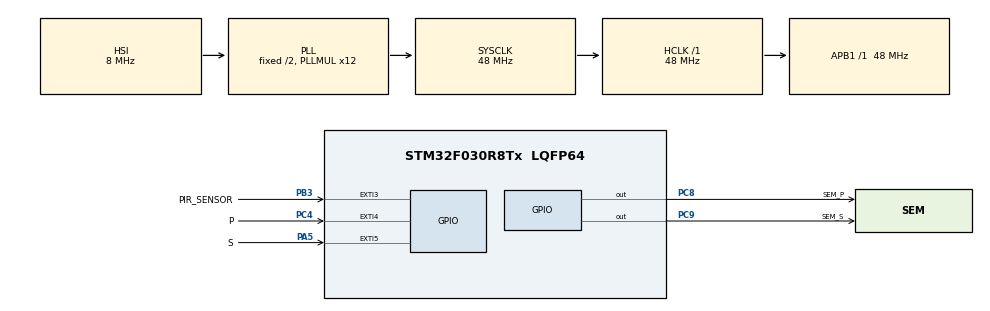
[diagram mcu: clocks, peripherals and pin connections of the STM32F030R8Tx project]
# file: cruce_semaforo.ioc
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Mcu.Family=STM32F0
Mcu.Name=STM32F030R8Tx
Mcu.Package=LQFP64
NVIC.EXTI2_3_IRQn=true\:0\:0\:false\:false\:true\:true
NVIC.EXTI4_15_IRQn=true\:0\:0\:false\:false\:true\:true
NVIC.TIM6_IRQn=true\:0\:0\:false\:false\:true\:true
PA13.GPIO_Label=SWDIO
PA13.Signal=SYS_SWDIO
PA14.GPIO_Label=SWCLK
PA14.Signal=SYS_SWCLK
PA5.GPIO_Label=S
PA5.GPIO_ModeDefaultEXTI=GPIO_MODE_IT_FALLING
PA5.GPIO_PuPd=GPIO_PULLUP
PA5.Signal=GPXTI5
PB3.GPIO_Label=PIR_SENSOR
PB3.GPIO_ModeDefaultEXTI=GPIO_MODE_IT_RISING
PB3.GPIO_PuPd=GPIO_PULLDOWN
PB3.Signal=GPXTI3
PC4.GPIO_Label=P
PC4.GPIO_PuPd=GPIO_PULLUP
PC4.Signal=GPXTI4
PC8.GPIO_Label=SEM_P
PC8.Signal=GPIO_Output
PC9.GPIO_Label=SEM_S
PC9.Signal=GPIO_Output
ProjectManager.HeapSize=0x200
ProjectManager.StackSize=0x400
ProjectManager.TargetToolchain=SW4STM32
RCC.AHBFreq_Value=48000000
RCC.APB1Freq_Value=48000000
RCC.APB1TimFreq_Value=48000000
RCC.HCLKFreq_Value=48000000
RCC.PLLMUL=RCC_PLL_MUL12
RCC.SYSCLKFreq_VALUE=48000000
RCC.SYSCLKSource=RCC_SYSCLKSOURCE_PLLCLK
TIM14.Period=29
TIM14.Prescaler=47999
TIM16.AutoReloadPreload=TIM_AUTORELOAD_PRELOAD_ENABLE
TIM16.Period=200
TIM16.Prescaler=47999
TIM17.AutoReloadPreload=TIM_AUTORELOAD_PRELOAD_ENABLE
TIM17.Period=200
TIM17.Prescaler=47999
TIM6.AutoReloadPreload=TIM_AUTORELOAD_PRELOAD_DISABLE
TIM6.Period=29
TIM6.Prescaler=47999
VP_TIM14_VS_ClockSourceINT.Mode=Enable_Timer
VP_TIM16_VS_ClockSourceINT.Mode=Enable_Timer
VP_TIM17_VS_ClockSourceINT.Mode=Enable_Timer
VP_TIM6_VS_ClockSourceINT.Mode=Enable_Timer
board=STM32F0308-DISCO

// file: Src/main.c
/**
  ******************************************************************************
  * @file           : main.c
  * @brief          : Main program body
  ******************************************************************************
  ** This notice applies to any and all portions of this file
  * that are not between comment pairs USER CODE BEGIN and
  * USER CODE END. Other portions of this file, whether
  * inserted by the user or by software development tools
  * are owned by their respective copyright owners.
  *
  * COPYRIGHT(c) 2018 STMicroelectronics
  *
  * Redistribution and use in source and binary forms, with or without modification,
  * are permitted provided that the following conditions are met:
  *   1. Redistributions of source code must retain the above copyright notice,
  *      this list of conditions and the following disclaimer.
  *   2. Redistributions in binary form must reproduce the above copyright notice,
  *      this list of conditions and the following disclaimer in the documentation
  *      and/or other materials provided with the distribution.
  *   3. Neither the name of STMicroelectronics nor the names of its contributors
  *      may be used to endorse or promote products derived from this software
  *      without specific prior written permission.
  *
  * THIS SOFTWARE IS PROVIDED BY THE COPYRIGHT HOLDERS AND CONTRIBUTORS "AS IS"
  * AND ANY EXPRESS OR IMPLIED WARRANTIES, INCLUDING, BUT NOT LIMITED TO, THE
  * IMPLIED WARRANTIES OF MERCHANTABILITY AND FITNESS FOR A PARTICULAR PURPOSE ARE
  * DISCLAIMED. IN NO EVENT SHALL THE COPYRIGHT HOLDER OR CONTRIBUTORS BE LIABLE
  * FOR ANY DIRECT, INDIRECT, INCIDENTAL, SPECIAL, EXEMPLARY, OR CONSEQUENTIAL
  * DAMAGES (INCLUDING, BUT NOT LIMITED TO, PROCUREMENT OF SUBSTITUTE GOODS OR
  * SERVICES; LOSS OF USE, DATA, OR PROFITS; OR BUSINESS INTERRUPTION) HOWEVER
  * CAUSED AND ON ANY THEORY OF LIABILITY, WHETHER IN CONTRACT, STRICT LIABILITY,
  * OR TORT (INCLUDING NEGLIGENCE OR OTHERWISE) ARISING IN ANY WAY OUT OF THE USE
  * OF THIS SOFTWARE, EVEN IF ADVISED OF THE POSSIBILITY OF SUCH DAMAGE.
  *
  ******************************************************************************
  */
#include "main.h"
#include "stm32f0xx_hal.h"

/* USER CODE BEGIN Includes */
#include "sem_fsm.h"
#include "fsm.h"
/* USER CODE END Includes */

TIM_HandleTypeDef htim6;
TIM_HandleTypeDef htim14;
TIM_HandleTypeDef htim16;
TIM_HandleTypeDef htim17;

/* USER CODE BEGIN PV */
/* Private variables ---------------------------------------------------------*/
uint32_t now,last,period;
/* USER CODE END PV */

void SystemClock_Config(void);
static void MX_GPIO_Init(void);
static void MX_TIM6_Init(void);
static void MX_TIM14_Init(void);
static void MX_TIM16_Init(void);
static void MX_TIM17_Init(void);

/* USER CODE BEGIN PFP */
/* Private function prototypes -----------------------------------------------*/

/* USER CODE END PFP */

int main(void)
{

  /* MCU Configuration----------------------------------------------------------*/

  /* Reset of all peripherals, Initializes the Flash interface and the Systick. */
  HAL_Init();

  /* Configure the system clock */
  SystemClock_Config();

  /* Initialize all configured peripherals */
  MX_GPIO_Init();
  MX_TIM6_Init();
  MX_TIM14_Init();
  MX_TIM16_Init();
  MX_TIM17_Init();
  /* USER CODE BEGIN 2 */
  systick_preescaler = 0;
  fsm_t * sem_p_fsm = new_sem_p_fsm();
  fsm_t * sem_s_fsm = new_sem_s_fsm();
  /* USER CODE END 2 */

  /* Infinite loop */
  /* USER CODE BEGIN WHILE */
  last = HAL_GetTick();
  period = 100;
  while (1)
  {
	 fsm_fire(sem_p_fsm);
	 fsm_fire(sem_s_fsm);
	 now = HAL_GetTick();
	 HAL_Delay( period - (now - last));
	 last = HAL_GetTick();

  /* USER CODE END WHILE */

  }

}

void SystemClock_Config(void)
{

  RCC_OscInitTypeDef RCC_OscInitStruct;
  RCC_ClkInitTypeDef RCC_ClkInitStruct;

    /**Initializes the CPU, AHB and APB busses clocks
    */
  RCC_OscInitStruct.OscillatorType = RCC_OSCILLATORTYPE_HSI;
  RCC_OscInitStruct.HSIState = RCC_HSI_ON;
  RCC_OscInitStruct.HSICalibrationValue = 16;
  RCC_OscInitStruct.PLL.PLLState = RCC_PLL_ON;
  RCC_OscInitStruct.PLL.PLLSource = RCC_PLLSOURCE_HSI;
  RCC_OscInitStruct.PLL.PLLMUL = RCC_PLL_MUL12;
  RCC_OscInitStruct.PLL.PREDIV = RCC_PREDIV_DIV1;
  if (HAL_RCC_OscConfig(&RCC_OscInitStruct) != HAL_OK)
  {
    _Error_Handler(__FILE__, __LINE__);
  }

    /**Initializes the CPU, AHB and APB busses clocks
    */
  RCC_ClkInitStruct.ClockType = RCC_CLOCKTYPE_HCLK|RCC_CLOCKTYPE_SYSCLK
                              |RCC_CLOCKTYPE_PCLK1;
  RCC_ClkInitStruct.SYSCLKSource = RCC_SYSCLKSOURCE_PLLCLK;
  RCC_ClkInitStruct.AHBCLKDivider = RCC_SYSCLK_DIV1;
  RCC_ClkInitStruct.APB1CLKDivider = RCC_HCLK_DIV1;

  if (HAL_RCC_ClockConfig(&RCC_ClkInitStruct, FLASH_LATENCY_1) != HAL_OK)
  {
    _Error_Handler(__FILE__, __LINE__);
  }

    /**Configure the Systick interrupt time
    */
  HAL_SYSTICK_Config(HAL_RCC_GetHCLKFreq()/1000);

    /**Configure the Systick
    */
  HAL_SYSTICK_CLKSourceConfig(SYSTICK_CLKSOURCE_HCLK);

  /* SysTick_IRQn interrupt configuration */
  HAL_NVIC_SetPriority(SysTick_IRQn, 0, 0);
}

/* TIM6 init function */
static void MX_TIM6_Init(void)
{

  htim6.Instance = TIM6;
  htim6.Init.Prescaler = 47999;
  htim6.Init.CounterMode = TIM_COUNTERMODE_UP;
  htim6.Init.Period = 29;
  htim6.Init.AutoReloadPreload = TIM_AUTORELOAD_PRELOAD_DISABLE;
  if (HAL_TIM_Base_Init(&htim6) != HAL_OK)
  {
    _Error_Handler(__FILE__, __LINE__);
  }

}

/* TIM14 init function */
static void MX_TIM14_Init(void)
{

  htim14.Instance = TIM14;
  htim14.Init.Prescaler = 47999;
  htim14.Init.CounterMode = TIM_COUNTERMODE_UP;
  htim14.Init.Period = 29;
  htim14.Init.ClockDivision = TIM_CLOCKDIVISION_DIV1;
  htim14.Init.AutoReloadPreload = TIM_AUTORELOAD_PRELOAD_DISABLE;
  if (HAL_TIM_Base_Init(&htim14) != HAL_OK)
  {
    _Error_Handler(__FILE__, __LINE__);
  }

}

/* TIM16 init function */
static void MX_TIM16_Init(void)
{

  htim16.Instance = TIM16;
  htim16.Init.Prescaler = 47999;
  htim16.Init.CounterMode = TIM_COUNTERMODE_UP;
  htim16.Init.Period = 200;
  htim16.Init.ClockDivision = TIM_CLOCKDIVISION_DIV1;
  htim16.Init.RepetitionCounter = 0;
  htim16.Init.AutoReloadPreload = TIM_AUTORELOAD_PRELOAD_ENABLE;
  if (HAL_TIM_Base_Init(&htim16) != HAL_OK)
  {
    _Error_Handler(__FILE__, __LINE__);
  }

}

/* TIM17 init function */
static void MX_TIM17_Init(void)
{

  htim17.Instance = TIM17;
  htim17.Init.Prescaler = 47999;
  htim17.Init.CounterMode = TIM_COUNTERMODE_UP;
  htim17.Init.Period = 200;
  htim17.Init.ClockDivision = TIM_CLOCKDIVISION_DIV1;
  htim17.Init.RepetitionCounter = 0;
  htim17.Init.AutoReloadPreload = TIM_AUTORELOAD_PRELOAD_ENABLE;
  if (HAL_TIM_Base_Init(&htim17) != HAL_OK)
  {
    _Error_Handler(__FILE__, __LINE__);
  }

}

/** Configure pins as
        * Analog
        * Input
        * Output
        * EVENT_OUT
        * EXTI
*/
static void MX_GPIO_Init(void)
{

  GPIO_InitTypeDef GPIO_InitStruct;

  /* GPIO Ports Clock Enable */
  __HAL_RCC_GPIOA_CLK_ENABLE();
  __HAL_RCC_GPIOC_CLK_ENABLE();
  __HAL_RCC_GPIOB_CLK_ENABLE();

  /*Configure GPIO pin Output Level */
  HAL_GPIO_WritePin(GPIOC, SEM_P_Pin|SEM_S_Pin, GPIO_PIN_RESET);

  /*Configure GPIO pin : S_Pin */
  GPIO_InitStruct.Pin = S_Pin;
  GPIO_InitStruct.Mode = GPIO_MODE_IT_FALLING;
  GPIO_InitStruct.Pull = GPIO_PULLUP;
  HAL_GPIO_Init(S_GPIO_Port, &GPIO_InitStruct);

  /*Configure GPIO pin : P_Pin */
  GPIO_InitStruct.Pin = P_Pin;
  GPIO_InitStruct.Mode = GPIO_MODE_IT_RISING;
  GPIO_InitStruct.Pull = GPIO_PULLUP;
  HAL_GPIO_Init(P_GPIO_Port, &GPIO_InitStruct);

  /*Configure GPIO pins : SEM_P_Pin SEM_S_Pin */
  GPIO_InitStruct.Pin = SEM_P_Pin|SEM_S_Pin;
  GPIO_InitStruct.Mode = GPIO_MODE_OUTPUT_PP;
  GPIO_InitStruct.Pull = GPIO_NOPULL;
  GPIO_InitStruct.Speed = GPIO_SPEED_FREQ_LOW;
  HAL_GPIO_Init(GPIOC, &GPIO_InitStruct);

  /*Configure GPIO pin : PIR_SENSOR_Pin */
  GPIO_InitStruct.Pin = PIR_SENSOR_Pin;
  GPIO_InitStruct.Mode = GPIO_MODE_IT_RISING;
  GPIO_InitStruct.Pull = GPIO_PULLDOWN;
  HAL_GPIO_Init(PIR_SENSOR_GPIO_Port, &GPIO_InitStruct);

  /* EXTI interrupt init*/
  HAL_NVIC_SetPriority(EXTI2_3_IRQn, 0, 0);
  HAL_NVIC_EnableIRQ(EXTI2_3_IRQn);

  HAL_NVIC_SetPriority(EXTI4_15_IRQn, 0, 0);
  HAL_NVIC_EnableIRQ(EXTI4_15_IRQn);

}

void _Error_Handler(char *file, int line)
{
  while(1)
  {
  }
}

/************************ (C) COPYRIGHT STMicroelectronics *****END OF FILE****/
